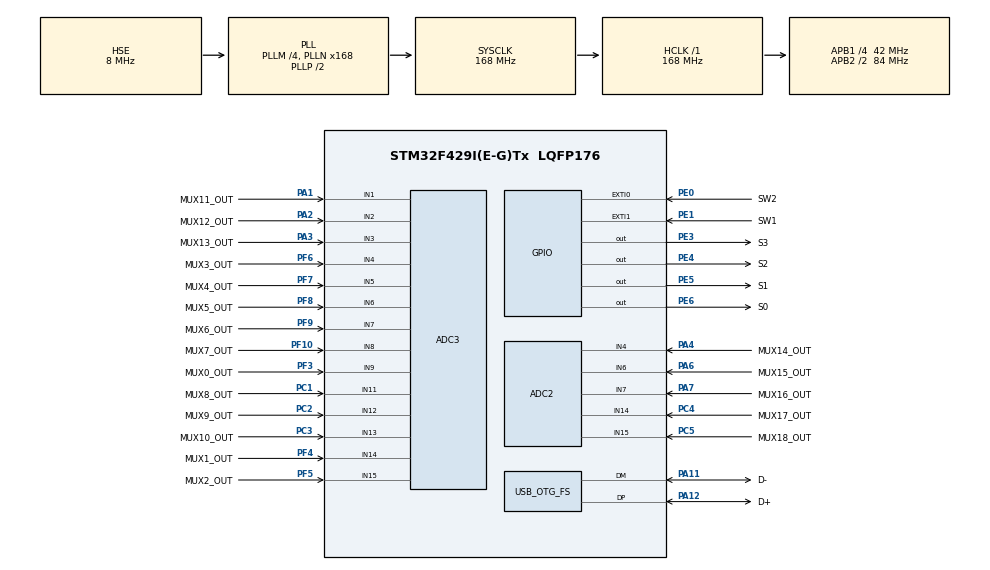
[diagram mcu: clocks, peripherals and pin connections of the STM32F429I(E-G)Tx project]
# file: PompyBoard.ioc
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ADC2.Channel-0\#ChannelRegularConversion=ADC_CHANNEL_4
ADC2.Channel-1\#ChannelRegularConversion=ADC_CHANNEL_6
ADC2.Channel-2\#ChannelRegularConversion=ADC_CHANNEL_7
ADC2.Channel-3\#ChannelRegularConversion=ADC_CHANNEL_14
ADC2.Channel-4\#ChannelRegularConversion=ADC_CHANNEL_15
ADC2.ClockPrescaler=ADC_CLOCK_SYNC_PCLK_DIV4
ADC2.ContinuousConvMode=ENABLE
ADC2.EOCSelection=ADC_EOC_SEQ_CONV
ADC2.NbrOfConversion=5
ADC2.NbrOfConversionFlag=1
ADC2.Rank-0\#ChannelRegularConversion=1
ADC2.Rank-1\#ChannelRegularConversion=2
ADC2.Rank-2\#ChannelRegularConversion=3
ADC2.Rank-3\#ChannelRegularConversion=4
ADC2.Rank-4\#ChannelRegularConversion=5
ADC2.SamplingTime-0\#ChannelRegularConversion=ADC_SAMPLETIME_480CYCLES
ADC2.SamplingTime-1\#ChannelRegularConversion=ADC_SAMPLETIME_480CYCLES
ADC2.SamplingTime-2\#ChannelRegularConversion=ADC_SAMPLETIME_480CYCLES
ADC2.SamplingTime-3\#ChannelRegularConversion=ADC_SAMPLETIME_480CYCLES
ADC2.SamplingTime-4\#ChannelRegularConversion=ADC_SAMPLETIME_480CYCLES
ADC2.ScanConvMode=ENABLE
ADC3.Channel-0\#ChannelRegularConversion=ADC_CHANNEL_9
ADC3.Channel-1\#ChannelRegularConversion=ADC_CHANNEL_14
ADC3.Channel-10\#ChannelRegularConversion=ADC_CHANNEL_13
ADC3.Channel-11\#ChannelRegularConversion=ADC_CHANNEL_1
ADC3.Channel-12\#ChannelRegularConversion=ADC_CHANNEL_2
ADC3.Channel-13\#ChannelRegularConversion=ADC_CHANNEL_3
ADC3.Channel-2\#ChannelRegularConversion=ADC_CHANNEL_15
ADC3.Channel-3\#ChannelRegularConversion=ADC_CHANNEL_4
ADC3.Channel-4\#ChannelRegularConversion=ADC_CHANNEL_5
ADC3.Channel-5\#ChannelRegularConversion=ADC_CHANNEL_6
ADC3.Channel-6\#ChannelRegularConversion=ADC_CHANNEL_7
ADC3.Channel-7\#ChannelRegularConversion=ADC_CHANNEL_8
ADC3.Channel-8\#ChannelRegularConversion=ADC_CHANNEL_11
ADC3.Channel-9\#ChannelRegularConversion=ADC_CHANNEL_12
ADC3.ClockPrescaler=ADC_CLOCK_SYNC_PCLK_DIV4
ADC3.ContinuousConvMode=ENABLE
ADC3.EOCSelection=ADC_EOC_SEQ_CONV
ADC3.NbrOfConversion=14
ADC3.NbrOfConversionFlag=1
ADC3.Rank-0\#ChannelRegularConversion=1
ADC3.Rank-1\#ChannelRegularConversion=2
ADC3.Rank-10\#ChannelRegularConversion=11
ADC3.Rank-11\#ChannelRegularConversion=12
ADC3.Rank-12\#ChannelRegularConversion=13
ADC3.Rank-13\#ChannelRegularConversion=14
ADC3.Rank-2\#ChannelRegularConversion=3
ADC3.Rank-3\#ChannelRegularConversion=4
ADC3.Rank-4\#ChannelRegularConversion=5
ADC3.Rank-5\#ChannelRegularConversion=6
ADC3.Rank-6\#ChannelRegularConversion=7
ADC3.Rank-7\#ChannelRegularConversion=8
ADC3.Rank-8\#ChannelRegularConversion=9
ADC3.Rank-9\#ChannelRegularConversion=10
ADC3.SamplingTime-0\#ChannelRegularConversion=ADC_SAMPLETIME_480CYCLES
ADC3.SamplingTime-1\#ChannelRegularConversion=ADC_SAMPLETIME_480CYCLES
ADC3.SamplingTime-10\#ChannelRegularConversion=ADC_SAMPLETIME_480CYCLES
ADC3.SamplingTime-11\#ChannelRegularConversion=ADC_SAMPLETIME_480CYCLES
ADC3.SamplingTime-12\#ChannelRegularConversion=ADC_SAMPLETIME_480CYCLES
ADC3.SamplingTime-13\#ChannelRegularConversion=ADC_SAMPLETIME_480CYCLES
ADC3.SamplingTime-2\#ChannelRegularConversion=ADC_SAMPLETIME_480CYCLES
ADC3.SamplingTime-3\#ChannelRegularConversion=ADC_SAMPLETIME_480CYCLES
ADC3.SamplingTime-4\#ChannelRegularConversion=ADC_SAMPLETIME_480CYCLES
ADC3.SamplingTime-5\#ChannelRegularConversion=ADC_SAMPLETIME_480CYCLES
ADC3.SamplingTime-6\#ChannelRegularConversion=ADC_SAMPLETIME_480CYCLES
ADC3.SamplingTime-7\#ChannelRegularConversion=ADC_SAMPLETIME_480CYCLES
ADC3.SamplingTime-8\#ChannelRegularConversion=ADC_SAMPLETIME_480CYCLES
ADC3.SamplingTime-9\#ChannelRegularConversion=ADC_SAMPLETIME_480CYCLES
ADC3.ScanConvMode=ENABLE
Dma.ADC2.1.Direction=DMA_PERIPH_TO_MEMORY
Dma.ADC2.1.FIFOMode=DMA_FIFOMODE_DISABLE
Dma.ADC2.1.Instance=DMA2_Stream2
Dma.ADC2.1.MemDataAlignment=DMA_MDATAALIGN_HALFWORD
Dma.ADC2.1.MemInc=DMA_MINC_ENABLE
Dma.ADC2.1.Mode=DMA_CIRCULAR
Dma.ADC2.1.PeriphDataAlignment=DMA_PDATAALIGN_HALFWORD
Dma.ADC2.1.PeriphInc=DMA_PINC_DISABLE
Dma.ADC2.1.Priority=DMA_PRIORITY_VERY_HIGH
Dma.ADC3.0.Direction=DMA_PERIPH_TO_MEMORY
Dma.ADC3.0.FIFOMode=DMA_FIFOMODE_DISABLE
Dma.ADC3.0.Instance=DMA2_Stream0
Dma.ADC3.0.MemDataAlignment=DMA_MDATAALIGN_HALFWORD
Dma.ADC3.0.MemInc=DMA_MINC_ENABLE
Dma.ADC3.0.Mode=DMA_CIRCULAR
Dma.ADC3.0.PeriphDataAlignment=DMA_PDATAALIGN_HALFWORD
Dma.ADC3.0.PeriphInc=DMA_PINC_DISABLE
Dma.ADC3.0.Priority=DMA_PRIORITY_VERY_HIGH
Dma.Request0=ADC3
Dma.Request1=ADC2
Mcu.Family=STM32F4
Mcu.Name=STM32F429I(E-G)Tx
Mcu.Package=LQFP176
NVIC.ADC_IRQn=true\:0\:0\:false\:false\:true\:true\:true\:true
NVIC.DMA2_Stream0_IRQn=true\:0\:0\:false\:false\:true\:false\:true\:true
NVIC.DMA2_Stream2_IRQn=true\:0\:0\:false\:false\:true\:false\:true\:true
NVIC.EXTI0_IRQn=true\:0\:0\:false\:false\:true\:true\:true\:true
NVIC.EXTI1_IRQn=true\:0\:0\:false\:false\:true\:true\:true\:true
NVIC.PriorityGroup=NVIC_PRIORITYGROUP_4
PA1.GPIO_Label=MUX11_OUT
PA1.Signal=ADCx_IN1
PA11.GPIO_Label=D-
PA11.Mode=Device_Only
PA11.Signal=USB_OTG_FS_DM
PA12.GPIO_Label=D+
PA12.Mode=Device_Only
PA12.Signal=USB_OTG_FS_DP
PA13.Mode=Serial_Wire
PA13.Signal=SYS_JTMS-SWDIO
PA14.Mode=Serial_Wire
PA14.Signal=SYS_JTCK-SWCLK
PA2.GPIO_Label=MUX12_OUT
PA2.Signal=ADCx_IN2
PA3.GPIO_Label=MUX13_OUT
PA3.Signal=ADCx_IN3
PA4.GPIO_Label=MUX14_OUT
PA4.Signal=ADCx_IN4
PA6.GPIO_Label=MUX15_OUT
PA6.Signal=ADCx_IN6
PA7.GPIO_Label=MUX16_OUT
PA7.Signal=ADCx_IN7
PC1.GPIO_Label=MUX8_OUT
PC1.Signal=ADCx_IN11
PC2.GPIO_Label=MUX9_OUT
PC2.Signal=ADCx_IN12
PC3.GPIO_Label=MUX10_OUT
PC3.Signal=ADCx_IN13
PC4.GPIO_Label=MUX17_OUT
PC4.Signal=ADCx_IN14
PC5.GPIO_Label=MUX18_OUT
PC5.Signal=ADCx_IN15
PE0.GPIO_Label=SW2
PE0.GPIO_PuPd=GPIO_PULLUP
PE0.Signal=GPXTI0
PE1.GPIO_Label=SW1
PE1.GPIO_PuPd=GPIO_PULLUP
PE1.Signal=GPXTI1
PE3.GPIO_Label=S3
PE3.Signal=GPIO_Output
PE4.GPIO_Label=S2
PE4.Signal=GPIO_Output
PE5.GPIO_Label=S1
PE5.Signal=GPIO_Output
PE6.GPIO_Label=S0
PE6.Signal=GPIO_Output
PF10.GPIO_Label=MUX7_OUT
PF10.Mode=IN8
PF10.Signal=ADC3_IN8
PF3.GPIO_Label=MUX0_OUT
PF3.Mode=IN9
PF3.Signal=ADC3_IN9
PF4.GPIO_Label=MUX1_OUT
PF4.Mode=IN14
PF4.Signal=ADC3_IN14
PF5.GPIO_Label=MUX2_OUT
PF5.Mode=IN15
PF5.Signal=ADC3_IN15
PF6.GPIO_Label=MUX3_OUT
PF6.Mode=IN4
PF6.Signal=ADC3_IN4
PF7.GPIO_Label=MUX4_OUT
PF7.Mode=IN5
PF7.Signal=ADC3_IN5
PF8.GPIO_Label=MUX5_OUT
PF8.Mode=IN6
PF8.Signal=ADC3_IN6
PF9.GPIO_Label=MUX6_OUT
PF9.Mode=IN7
PF9.Signal=ADC3_IN7
PH0/OSC_IN.Mode=HSE-External-Oscillator
PH0/OSC_IN.Signal=RCC_OSC_IN
PH1/OSC_OUT.Mode=HSE-External-Oscillator
PH1/OSC_OUT.Signal=RCC_OSC_OUT
ProjectManager.HeapSize=0x200
ProjectManager.StackSize=0x400
ProjectManager.TargetToolchain=STM32CubeIDE
RCC.48MHZClocksFreq_Value=48000000
RCC.AHBFreq_Value=168000000
RCC.APB1CLKDivider=RCC_HCLK_DIV4
RCC.APB1Freq_Value=42000000
RCC.APB1TimFreq_Value=84000000
RCC.APB2CLKDivider=RCC_HCLK_DIV2
RCC.APB2Freq_Value=84000000
RCC.APB2TimFreq_Value=168000000
RCC.CortexFreq_Value=168000000
RCC.HCLKFreq_Value=168000000
RCC.HSE_VALUE=8000000
RCC.HSI_VALUE=16000000
RCC.LSE_VALUE=32768
RCC.PLLM=4
RCC.PLLN=168
RCC.PLLQ=7
RCC.SYSCLKFreq_VALUE=168000000
RCC.SYSCLKSource=RCC_SYSCLKSOURCE_PLLCLK
RCC.VCOOutputFreq_Value=336000000
SH.ADCx_IN1.0=ADC3_IN1,IN1
SH.ADCx_IN11.0=ADC3_IN11,IN11
SH.ADCx_IN12.0=ADC3_IN12,IN12
SH.ADCx_IN13.0=ADC3_IN13,IN13
SH.ADCx_IN14.0=ADC2_IN14,IN14
SH.ADCx_IN15.0=ADC2_IN15,IN15
SH.ADCx_IN2.0=ADC3_IN2,IN2
SH.ADCx_IN3.0=ADC3_IN3,IN3
SH.ADCx_IN4.0=ADC2_IN4,IN4
SH.ADCx_IN6.0=ADC2_IN6,IN6
SH.ADCx_IN7.0=ADC2_IN7,IN7
USB_OTG_FS.VirtualMode=Device_Only
board=custom

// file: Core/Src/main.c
/* USER CODE BEGIN Header */
/**
  ******************************************************************************
  * @file           : main.c
  * @brief          : Main program body
  ******************************************************************************
  * @attention
  *
  * Copyright (c) 2025 STMicroelectronics.
  * All rights reserved.
  *
  * This software is licensed under terms that can be found in the LICENSE file
  * in the root directory of this software component.
  * If no LICENSE file comes with this software, it is provided AS-IS.
  *
  ******************************************************************************
  */
/* USER CODE END Header */
#include "main.h"
#include "adc.h"
#include "dma.h"
#include "usb_otg.h"
#include "gpio.h"

/* USER CODE BEGIN Includes */
#include "SensorMatrix.h"
/* USER CODE END Includes */

/* USER CODE BEGIN PV */
SensorMatrix sensorMatrix;
float sm_centerX = 0;
float sm_centerY = 0;
/* USER CODE END PV */

void SystemClock_Config(void);

int main(void)
{

  /* MCU Configuration--------------------------------------------------------*/

  /* Reset of all peripherals, Initializes the Flash interface and the Systick. */
  HAL_Init();

  /* Configure the system clock */
  SystemClock_Config();

  /* Initialize all configured peripherals */
  MX_GPIO_Init();
  MX_DMA_Init();
  MX_ADC2_Init();
  MX_ADC3_Init();
  MX_USB_OTG_FS_PCD_Init();
  /* USER CODE BEGIN 2 */
  SM_Init(&sensorMatrix, &hadc2, &hadc3, &hpcd_USB_OTG_FS);

  /* USER CODE END 2 */

  /* Infinite loop */
  while (1)
  {
	  float *pos = SM_Get_XY_Position(&sensorMatrix);
//	  printf("X: %.2f, Y: %.2f\r\n", pos[0], pos[1]);
//	  free(pos);

	  // for live expressions
      sm_centerX = pos[0];
      sm_centerY = pos[1];

      free(pos);
	  HAL_Delay(10);
  }
}

void SystemClock_Config(void)
{
  RCC_OscInitTypeDef RCC_OscInitStruct = {0};
  RCC_ClkInitTypeDef RCC_ClkInitStruct = {0};

  /** Configure the main internal regulator output voltage
  */
  __HAL_RCC_PWR_CLK_ENABLE();
  __HAL_PWR_VOLTAGESCALING_CONFIG(PWR_REGULATOR_VOLTAGE_SCALE1);

  /** Initializes the RCC Oscillators according to the specified parameters
  * in the RCC_OscInitTypeDef structure.
  */
  RCC_OscInitStruct.OscillatorType = RCC_OSCILLATORTYPE_HSE;
  RCC_OscInitStruct.HSEState = RCC_HSE_ON;
  RCC_OscInitStruct.PLL.PLLState = RCC_PLL_ON;
  RCC_OscInitStruct.PLL.PLLSource = RCC_PLLSOURCE_HSE;
  RCC_OscInitStruct.PLL.PLLM = 4;
  RCC_OscInitStruct.PLL.PLLN = 168;
  RCC_OscInitStruct.PLL.PLLP = RCC_PLLP_DIV2;
  RCC_OscInitStruct.PLL.PLLQ = 7;
  if (HAL_RCC_OscConfig(&RCC_OscInitStruct) != HAL_OK)
  {
    Error_Handler();
  }

  /** Initializes the CPU, AHB and APB buses clocks
  */
  RCC_ClkInitStruct.ClockType = RCC_CLOCKTYPE_HCLK|RCC_CLOCKTYPE_SYSCLK
                              |RCC_CLOCKTYPE_PCLK1|RCC_CLOCKTYPE_PCLK2;
  RCC_ClkInitStruct.SYSCLKSource = RCC_SYSCLKSOURCE_PLLCLK;
  RCC_ClkInitStruct.AHBCLKDivider = RCC_SYSCLK_DIV1;
  RCC_ClkInitStruct.APB1CLKDivider = RCC_HCLK_DIV4;
  RCC_ClkInitStruct.APB2CLKDivider = RCC_HCLK_DIV2;

  if (HAL_RCC_ClockConfig(&RCC_ClkInitStruct, FLASH_LATENCY_5) != HAL_OK)
  {
    Error_Handler();
  }
}

void Error_Handler(void)
{
  __disable_irq();
  while (1)
  {
  }
}
